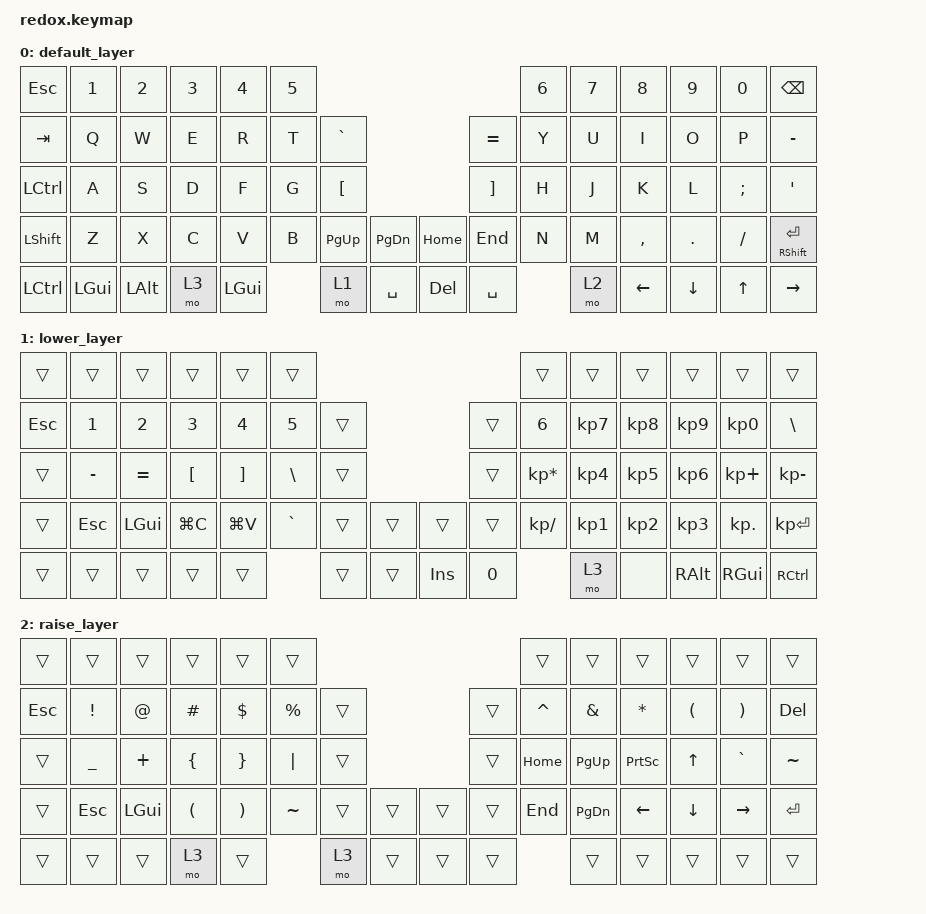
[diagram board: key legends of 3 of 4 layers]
/*
 * Copyright (c) 2021 The ZMK Contributors
 *
 * SPDX-License-Identifier: MIT
 */

#include <behaviors.dtsi>
#include <dt-bindings/zmk/keys.h>
#include <dt-bindings/zmk/bt.h>
#include <dt-bindings/zmk/ext_power.h>
#include <dt-bindings/zmk/outputs.h>
#include <dt-bindings/zmk/pointing.h>

/ {
    keymap {
        compatible =  "zmk,keymap" ;

        default_layer {
// --------------------------------------------------------------------------------------------------------------------------------
// | ESC     |  1!    |  2@    |   3#  |  4$    |  5%  |                     -                    |  6^   |  7&    |  8*     |  9(    | 0)     |    BSPC   |
// | TAB     |  Q     |  W     |   E   |  R     |  T   |   `~  |             -          |  =+     |  Y    |  U     |  I      |  O     | P      |     -_    |
// | CTRL    |  A     |  S     |   D   |  F     |  G   |   [   |             -          |  ]      |  H    |  J     |  K      |  L     | ;:     |     '"    |
// | SHIFT   |  Z     |  X     |   C   |  V     |  B   | PG_UP | PG_DOWN   | - | HOME   | END     |  N    |  M     |  ,      |  .     | /      | SHFT(RET) |
// | CRTL    | ALT    | GUI    | LOWER |    GUI | ---- | LOWER | SPACE     | - | DEL    | SPACE   | ----- | RAISE  | LEFT    | DOWN   | UP     |   RIGHT   |
            bindings = <
    &kp ESC   &kp N1   &kp N2   &kp N3  &kp N4   &kp N5                                            &kp N6    &kp N7 &kp N8    &kp N9   &kp N0   &kp BSPC
    &kp TAB   &kp Q    &kp W    &kp E   &kp R    &kp T  &kp GRAVE                        &kp EQUAL &kp Y     &kp U  &kp I     &kp O    &kp P    &kp MINUS
    &kp LCTRL &kp A    &kp S    &kp D   &kp F    &kp G  &kp LBKT                         &kp RBKT  &kp H     &kp J  &kp K     &kp L    &kp SEMI &kp SQT
    &kp LSHFT &kp Z    &kp X    &kp C   &kp V    &kp B  &kp PG_UP &kp PG_DN     &kp HOME &kp END   &kp N     &kp M  &kp COMMA &kp DOT  &kp FSLH &mt RSHFT RET
    &kp LCTRL &kp LGUI &kp LALT &mo 3   &kp LGUI        &mo 1     &kp SPACE     &kp DEL  &kp SPACE           &mo 2  &kp LEFT  &kp DOWN &kp UP   &kp RIGHT
            >;

        };

        lower_layer {
// -----------------------------------------------------------------------------------------------------------------------------------------------------------------
// | ESC   |  1      |  2      |   3     |   4     |  5      |                   -                |  6            |  7      |   8     |  9      |  0        |  DEL       |
// | ESC   |  1      |  2      |   3     |   4     |  5      |   (   |           -        |  )    |  6            |  NUM 7  |   NUM 8 |  NUM 9  |  NUM 0    |  \|        |
// | CTRL  |  -      |  =      |   [     |   ]     |  \      |   [   |           -        |  ]    |  *            |  NUM 4  |   NUM 5 |  NUM 6  |  NUM +    |   -        |
// | SHIFT | ESC     | GUI     | COPY    | PASTE   |         | PG_UP | PG_DOWN | - | HOME | END   |  \            |  NUM 1  |   NUM 2 |  NUM 3  | NUM .     | NUM ENTER  |
// | CRTL  | ALT     | GUI     | LOWER   |     GUI | ------- | LOWER | SPACE   | - | DEL  |  0    | ------------- | RAISE   |         | RALT    | RGUI      | RCTRL      |
            bindings = <
    &trans  &trans    &trans    &trans    &trans    &trans                                         &trans          &trans    &trans    &trans    &trans      &trans
    &kp ESC &kp N1    &kp N2    &kp N3    &kp N4    &kp N5    &trans                        &trans &kp N6          &kp KP_N7 &kp KP_N8 &kp KP_N9 &kp KP_N0   &kp BSLH
    &trans  &kp MINUS &kp EQUAL &kp LBKT  &kp RBKT  &kp BSLH  &trans                        &trans &kp KP_MULTIPLY &kp KP_N4 &kp KP_N5 &kp KP_N6 &kp KP_PLUS &kp KP_MINUS
    &trans  &kp ESC   &kp LGUI  &kp LG(C) &kp LG(V) &kp GRAVE &trans &trans         &trans  &trans &kp KP_DIVIDE   &kp KP_N1 &kp KP_N2 &kp KP_N3 &kp KP_DOT  &kp KP_ENTER
    &trans  &trans    &trans    &trans    &trans              &trans &trans         &kp INS &kp N0                 &mo 3     &none     &kp RALT  &kp RGUI    &kp RCTRL
            >;
        };

        raise_layer {
// ----------------------------------------------------------------------------------------------------------------------------
// | ESC   |  1  |  2  |   3   |  4  |  5  |                   ---                |  6   |  7   |  8   |  9   |  0    |  DEL  |
// | ESC   |  !  |  @  |   #   |  $  |  %  |   (   |           ---        |  )    |  ^   |  &   |  *   |  (   |  )    |  DEL  |
// | CTRL  |  _  |  +  |   {   |  }  | "|" |   [   |           ---        |  ]    | HOME | PGUP | PRSC | UP   |  `    |   ~   |
// | SHIFT | ESC | GUI |   (   |  )  |     | PG_UP | PG_DOWN | --- | HOME | END   | END  | PGDN | LEFT | DOWN | RIGHT |  RET  |
// | CRTL  | ALT | GUI | LOWER |    GUI    | LOWER | SPACE   | --- | DEL  | SPACE |    RAISE    | LEFT | DOWN | UP    | RIGHT |
            bindings = <
   &trans  &trans    &trans   &trans   &trans   &trans                                &trans    &trans    &trans    &trans   &trans    &trans
   &kp ESC &kp EXCL  &kp AT   &kp HASH &kp DLLR &kp PRCNT &trans               &trans &kp CARET &kp AMPS  &kp ASTRK &kp LPAR &kp RPAR  &kp DEL
   &trans  &kp UNDER &kp PLUS &kp LBRC &kp RBRC &kp PIPE  &trans               &trans &kp HOME  &kp PG_UP &kp PSCRN &kp UP   &kp GRAVE &kp TILDE
   &trans  &kp ESC   &kp LGUI &kp LPAR &kp RPAR &kp TILDE &trans &trans &trans &trans &kp END   &kp PG_DN &kp LEFT  &kp DOWN &kp RIGHT &kp RET
   &trans  &trans    &trans   &mo 3         &trans        &mo 3  &trans &trans &trans        &trans       &trans    &trans   &trans    &trans
            >;
        };

        adjust_layer {
// -----------------------------------------------------------------------------------------
// |  ESC  |  F1      |    F2      |    F3     |     F4     | F5       |                 -                   | F6         | F7         |  F8          |  F9          | F10        |
   |
// | TAB   |          |            |           |            |          | BOOTL |         -        | BTCLR    | BT1        | BT2        |  BT3         |  BT4         | BT5        | OUTPUT T
GL |
// | CTRL  | MUTE     |  Vol Dn    |  Vol Up   | Play/Pause |          | RESET |         -        |          | F1         | F2         |  F3          |  F4          | F5         | F6
   |
// | SHIFT | PSCRN    |  PSCRN     |   CAPS    | Next Track |          | PG_UP | PG_DN | - | HOME | END      | F7         | F8         |  F9          |  F10         | F11        |
   |
// | CRTL  | ALT      |  GUI       |   LOWER   |      GUI   | -------- | LOWER | SPACE | - | DEL  | SPACE    | ---------- | RAISE      | LEFT         | DOWN         | UP         |   RIGHT
   |
                        bindings = <
    //&trans  &kp F1     &kp F2       &kp F3      &kp F4       &kp F5                                           &kp F6       &kp F7       &kp F8         &kp F9         &kp F10      &trans
    //&trans  &kp F11    &kp F12      &none       &kp C_VOL_UP &none      &bootloader                &bt BT_CLR &bt BT_SEL 0 &bt BT_SEL 1 &bt BT_SEL 2   &bt BT_SEL 3   &bt BT_SEL 4 &out OU
T_TOG
    //&trans  &kp C_MUTE &kp C_VOL_DN &kp C_PREV  &kp C_PP     &kp C_NEXT &sys_reset                 &none      &kp F1       &none        &none          &none          &none        &none
    //&trans  &kp PSCRN  &kp PSCRN    &kp CLCK    &kp C_VOL_DN &none      &trans  &trans      &trans &trans     &kp F7       &none        &none          &none          &none        &none
    //&trans  &trans     &trans       &trans      &trans                  &trans  &trans      &trans &trans                  &trans       &none          &none          &none        &none

    &trans  &kp F1     &kp F2       &kp F3      &kp F4       &kp F5                                           &kp F6       &kp F7         &kp F8         &kp F9         &kp F10      &trans
    &trans  &kp F11    &kp F12      &none       &kp C_VOL_UP &none      &bootloader                &bt BT_CLR &bt BT_SEL 0 &bt BT_SEL 1   &bt BT_SEL 2   &bt BT_SEL 3   &bt BT_SEL 4 &out OU
T_TOG
    &trans  &kp C_MUTE &kp C_VOL_DN &kp C_PREV  &kp C_PP     &kp C_NEXT &sys_reset                 &none      &kp F1       &msc SCRL_UP   &none          &none          &none        &none
    &trans  &kp PSCRN  &kp PSCRN    &kp CLCK    &kp C_VOL_DN &none      &trans  &trans      &trans &trans     &kp F7       &msc SCRL_DOWN &mkp MB1       &mkp MB3       &mkp MB2     &none
    &trans  &trans     &trans       &trans      &trans                  &trans  &trans      &trans &trans                  &trans         &mmv MOVE_LEFT &mmv MOVE_DOWN &mmv MOVE_UP &mmv MO
VE_RIGHT

>;
        };
    };
};
